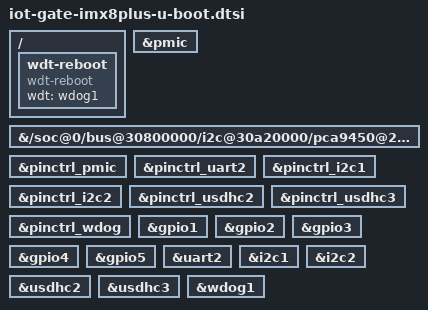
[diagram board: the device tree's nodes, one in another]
// SPDX-License-Identifier: GPL-2.0+
/*
 * Copyright 2024 CompuLab / 4Sigma
 *
 * U-Boot/SPL bits for the IOT-GATE-IMX8PLUS. Mainline binman flow
 * (imx8mp-u-boot.dtsi) plus bootph-* tags marking the nodes the SPL needs:
 * console (uart2), PMIC over i2c1 (DDR voltages), SoM EEPROM over i2c2 (DDR
 * timing descriptor), the eMMC/SD controllers and the watchdog.
 *
 * NOTE: the vendor fork uses the legacy u-boot,dm-spl tags; mainline v2026.04
 * requires bootph-* (u-boot,dm-pre-reloc -> bootph-all, u-boot,dm-spl ->
 * bootph-pre-ram), which is what we use here.
 */

#include "imx8mp-u-boot.dtsi"

/ {
	wdt-reboot {
		compatible = "wdt-reboot";
		wdt = <&wdog1>;
		bootph-pre-ram;
	};
};

&pmic {
	bootph-pre-ram;
};

&{/soc@0/bus@30800000/i2c@30a20000/pca9450@25/regulators} {
	bootph-pre-ram;
};

&pinctrl_pmic {
	bootph-pre-ram;
};

&pinctrl_uart2 {
	bootph-pre-ram;
};

&pinctrl_i2c1 {
	bootph-pre-ram;
};

&pinctrl_i2c2 {
	bootph-pre-ram;
};

&pinctrl_usdhc2 {
	bootph-pre-ram;
};

&pinctrl_usdhc3 {
	bootph-pre-ram;
};

&pinctrl_wdog {
	bootph-pre-ram;
};

&gpio1 {
	bootph-pre-ram;
};

&gpio2 {
	bootph-pre-ram;
};

&gpio3 {
	bootph-pre-ram;
};

&gpio4 {
	bootph-pre-ram;
};

&gpio5 {
	bootph-pre-ram;
};

&uart2 {
	bootph-pre-ram;
};

&i2c1 {
	bootph-pre-ram;
};

&i2c2 {
	bootph-pre-ram;
};

&usdhc2 {
	bootph-pre-ram;
};

&usdhc3 {
	bootph-pre-ram;
};

&wdog1 {
	bootph-pre-ram;
};
